AUTOSAR XML (schema 4.0)
package /S09SDK/If
  sender receiver interface InfoLink
    data val
  sender receiver interface BodyCmd
    data val
package /S09SDK/Swc
  application sw component type HeadUnit
    provide port ivitogwOut: provided-interface=InfoLink
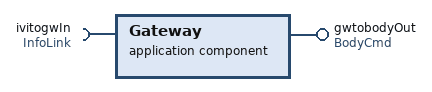
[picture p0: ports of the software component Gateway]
  application sw component type Gateway
    provide port gwtobodyOut: provided-interface=BodyCmd
    require port ivitogwIn: required-interface=InfoLink
  application sw component type BodyCtrl
    require port gwtobodyIn: required-interface=BodyCmd
  composition sw component type Root
    component ivi: type=HeadUnit
    component gw: type=Gateway
    component body: type=BodyCtrl
    connect ivi.ivitogwOut -> gw.ivitogwIn
    connect gw.gwtobodyOut -> body.gwtobodyIn
package /S09SDK/Comm
  pdu ivitogwIPdu
    signal ivitogwISig: system signal ivitogwSSig
  secured i pdu ivitogwSecuredIPdu: auth-info-tx-length=32, freshness-value-id=1, freshness-value-length=8, payload=ivitogwIPdu
  pdu gwtobodyIPdu
    signal gwtobodyISig: system signal gwtobodySSig
  secured i pdu gwtobodySecuredIPdu: auth-info-tx-length=32, freshness-value-id=1, freshness-value-length=8, payload=gwtobodyIPdu
package /S09SDK/Topology
  ecu instance BodyEcu
  ecu instance GatewayEcu
  ecu instance TelematicsEcu
  system Veh
    root-software-compositions:
      root sw composition prototype Root: software-composition=Root
    system mapping Map
      data-mappings:
        data-element=Root.ivitogwOut.val, system-signal=ivitogwSSig
        data-element=Root.gwtobodyOut.val, system-signal=gwtobodySSig
      sw-mappings:
        swc to ecu mapping ToBodyEcu: component=body, ecu-instance=BodyEcu
        swc to ecu mapping ToGatewayEcu: component=gw, ecu-instance=GatewayEcu
        swc to ecu mapping ToTelematicsEcu: component=ivi, ecu-instance=TelematicsEcu
